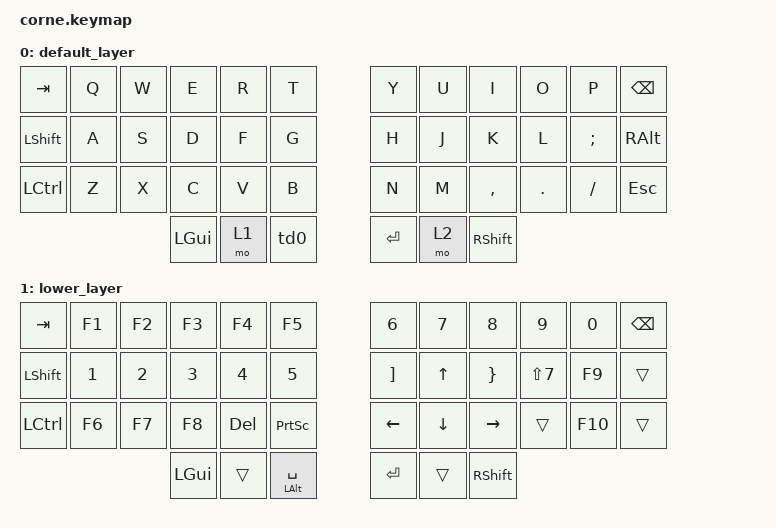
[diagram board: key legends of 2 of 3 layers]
#include <behaviors.dtsi>
#include <dt-bindings/zmk/keys.h>
#include <dt-bindings/zmk/bt.h>

/ { 
   behaviors {
        td0: tap_dance_0 {
            compatible = "zmk,behavior-tap-dance";
            #binding-cells = <0>;
            tapping-term-ms = <200>;
            bindings = <&kp SPACE>, <&kp LALT>;
        };
    };
        keymap {
                compatible = "zmk,keymap";
                default_layer {
// ------------------------------teclas en español ---------------------------------------------
// |  TAB |  Q  |  W  |  E  |  R  |  T  |   |  Y  |  U   |  I  |  O  |  P  | BSPC |
// | SHFT |  A  |  S  |  D  |  F  |  G  |   |  H  |  J   |  K  |  L  |  Ñ  | RALT |
// | CTRL |  Z  |  X  |  C  |  V  |  B  |   |  N  |  M   |  ,  |  .  |  -  | ESC  |
//                    | GUI | LWR | SPC(LALT) |   | ENT | RSE  | SHFT |
                        bindings = <
   &kp TAB   &kp Q &kp W &kp E &kp R &kp T   &kp Y &kp U  &kp I     &kp O   &kp P    &kp BSPC
   &kp LSHFT &kp A &kp S &kp D &kp F &kp G   &kp H &kp J  &kp K     &kp L   &kp SEMI &kp RALT
   &kp LCTRL &kp Z &kp X &kp C &kp V &kp B   &kp N &kp M  &kp COMMA &kp DOT &kp FSLH &kp ESC
             &kp LGUI &mo 1 &td0             &kp RET &mo 2 &kp RSHFT


                        >;
                };
                lower_layer {
// -----------------------------------------------------------------------------------------
// |  TAB | F1  | F2  | F3  | F4  | F5  |        |  6  |  7  |  8  |  9  |  0  | BSPC |
// | SHFT |  1  |  2  |  3  |  4  |  5  |        |  +  | UP  |  *  |   / |  F9 | RALT |
// |LCTRL |  F6 | F7  |  F8 | DEL |PSCRN|        | LFT | DWN | RGT |   . | F10 |  ESC |
//                    | GUI |     | SPC |        | ENT |     | SHFT |
                        bindings = <
   &kp TAB    &kp F1  &kp F2 &kp F3 &kp F4 &kp F5     &kp N6   &kp N7   &kp N8    &kp N9     &kp N0    &kp BSPC
   &kp LSHFT  &kp N1  &kp N2 &kp N3 &kp N4 &kp N5     &kp RBKT  &kp UP  &kp RBRC  &kp LS(N7) &kp F9    &trans
   &kp LCTRL  &kp F6  &kp F7 &kp F8 &kp DEL &kp PSCRN &kp LEFT &kp DOWN &kp RIGHT &trans     &kp F10   &trans
               &kp LGUI  &trans  &mt LALT SPACE       &kp RET  &trans   &kp RSHFT

                        >;
                };

                raise_layer {
// -----------------------------------------------------------------------------------------
// |  TAB |  !   |  ""     |  #  |  $  |  %  |   |  &   |    /  |  (  |  )   |  =  | BSPC |
// | CTRL |   <  |  vol̉+   |play | F11 | F12 |   | !    |  ¿ =  |  '  |  [   |  ]| |`     |
// | SHFT |   >  |   vol-  |     |     |     |   |   ^  |  ¡ +  |¨ {  |  }   | } \ | ° ~  |
//                         | GUI |     | SPC |   | ENT  |       | SHFT|
                        bindings = <
   &kp  TAB  &kp EXCL     &kp AT       &kp HASH  &kp DLLR &kp PRCNT    &kp CARET &kp AMPS  &kp LS(N8)  &kp LS(N9)    &kp RPAR &kp BSPC
   &kp LSHFT &kp NUBS     &kp C_VOL_UP &kp C_PP  &trans   &trans       &kp EXCL  &kp EQUAL &kp LBKT    &kp RA(LBKT)  &kp PIPE &kp GRAVE
   &kp LCTRL &kp LS(NUBS) &kp C_VOL_DN &trans    &trans   &trans       &kp RA(SQT) &kp UNDER &kp PLUS  &trans        &kp SQT  &kp BSLH &kp TILDE
                        &kp LGUI      &trans   &mt LALT SPACE          &kp RET   &trans    &kp RSHFT

                        >;
                };
        };
};
